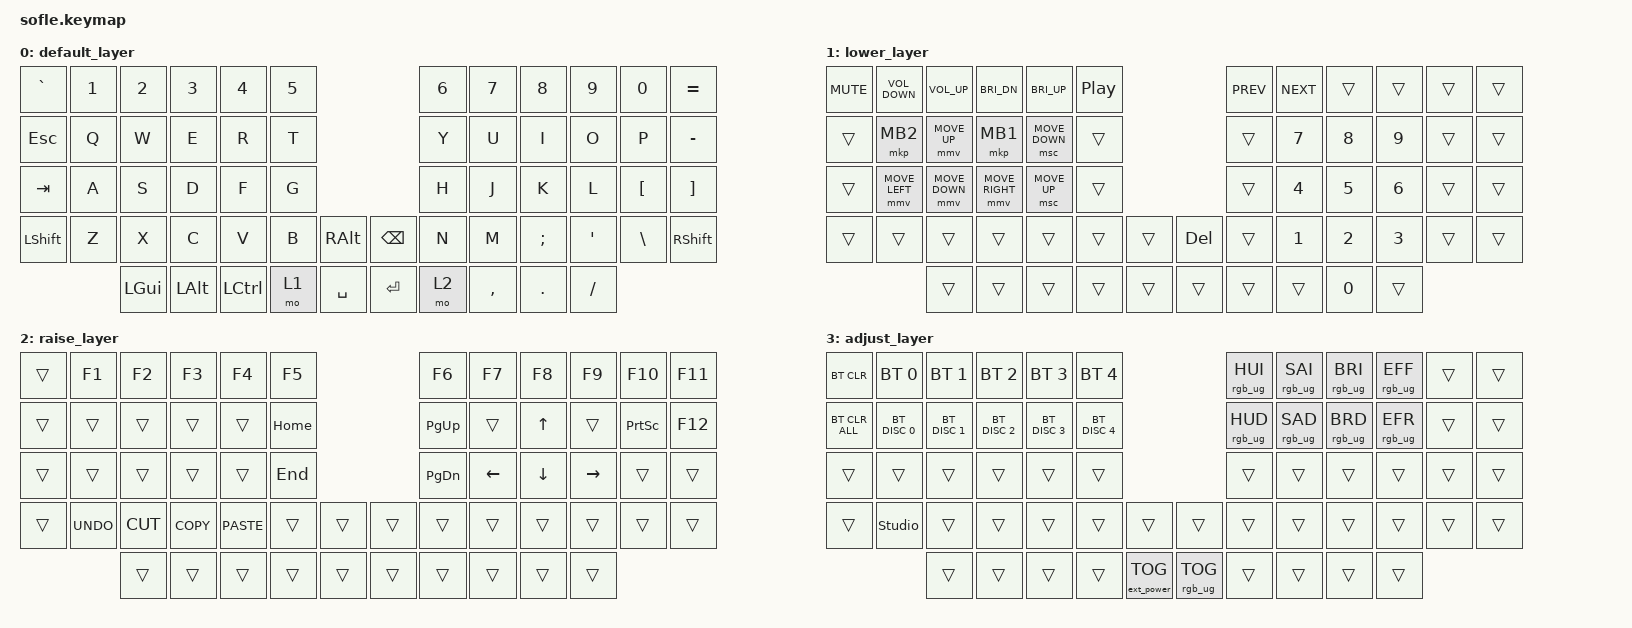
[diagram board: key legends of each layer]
/*
 * Copyright (c) 2020 The ZMK Contributors
 *
 * SPDX-License-Identifier: MIT
 */

#include <behaviors.dtsi>
#include <dt-bindings/zmk/keys.h>
#include <dt-bindings/zmk/bt.h>
#include <dt-bindings/zmk/ext_power.h>
#include <dt-bindings/zmk/rgb.h>
#define ZMK_POINTING_DEFAULT_MOVE_VAL 1500  // default: 600
#define ZMK_POINTING_DEFAULT_SCRL_VAL 20    // default: 10
#include <dt-bindings/zmk/pointing.h>

/*
 * Temporarily here because nice nano v2 spi is not defined on ZMK Yet
 * Source: https://github.com/zmkfirmware/zmk/blob/main/app/boards/shields/reviung41/boards/nice_nano.overlay
 * GitHub Issue: https://github.com/zmkfirmware/zmk/issues/885
 */

#include <dt-bindings/led/led.h>

&pinctrl {
    spi3_default: spi3_default {
        group1 {
            psels = <NRF_PSEL(SPIM_MOSI, 0, 8)>;
        };
    };

    spi3_sleep: spi3_sleep {
        group1 {
            psels = <NRF_PSEL(SPIM_MOSI, 0, 8)>;
            low-power-enable;
        };
    };
};

&spi3 {
    compatible = "nordic,nrf-spim";
    status = "okay";

    pinctrl-0 = <&spi3_default>;
    pinctrl-1 = <&spi3_sleep>;
    pinctrl-names = "default", "sleep";

    led_strip: ws2812@0 {
        compatible = "worldsemi,ws2812-spi";
        label = "WS2812";

        /* SPI */
        reg = <0>; /* ignored, but necessary for SPI bindings */
        spi-max-frequency = <4000000>;

        /* WS2812 */
        chain-length = <30>;
        spi-one-frame = <0x70>;
        spi-zero-frame = <0x40>;

        color-mapping = <LED_COLOR_ID_GREEN LED_COLOR_ID_RED LED_COLOR_ID_BLUE>;
    };
};

/ {
    chosen {
        zmk,underglow = &led_strip;
    };
};

/* END temporary RGB support section */


/ {
    combos {
        compatible = "zmk,combos";
        combo_esc {
            timeout-ms = <50>;
            key-positions = <0 1>;
            bindings = <&kp ESC>;
        };
        combo_del {
            timeout-ms = <50>;
            key-positions = <10 11>;
            bindings = <&kp DEL>;
        };
        combo_bspc {
            timeout-ms = <50>;
            key-positions = <22 23>;
            bindings = <&kp BSPC>;
        };
        combo_mb3 {
            timeout-ms = <50>;
            key-positions = <14 26>;
            bindings = <&mkp MB3>;
            layers = <1>;
        };
        combo_mb4 {
            timeout-ms = <50>;
            key-positions = <13 25>;
            bindings = <&mkp MB4>;
            layers = <1>;
        };
        combo_mb5 {
            timeout-ms = <50>;
            key-positions = <15 27>;
            bindings = <&mkp MB5>;
            layers = <1>;
        };
        combo_bootloader_left {
            // Pressing the 3 first keys on the keyboard will trigger &bootloader
            timeout-ms = <50>;
            key-positions = <0 1 2>;
            bindings = <&bootloader>;
        };
    };

    conditional_layers {
        compatible = "zmk,conditional-layers";
        tri_layer {
            if-layers = <1 2>;
            then-layer = <3>;
        };
    };

    keymap {
        compatible = "zmk,keymap";

        default_layer {
            bindings = <
//╭─────────────┬─────────────┬─────────────┬─────────────┬─────────────┬─────────────╮                             ╭─────────────┬─────────────┬─────────────┬─────────────┬─────────────┬─────────────╮
    &kp GRAVE     &kp N1        &kp N2        &kp N3        &kp N4        &kp N5                                      &kp N6        &kp N7        &kp N8        &kp N9        &kp N0        &kp EQUAL
//├─────────────┼─────────────┼─────────────┼─────────────┼─────────────┼─────────────┤                             ├─────────────┼─────────────┼─────────────┼─────────────┼─────────────┼─────────────┤
    &kp ESC       &kp Q         &kp W         &kp E         &kp R         &kp T                                       &kp Y         &kp U         &kp I         &kp O         &kp P         &kp MINUS
//├─────────────┼─────────────┼─────────────┼─────────────┼─────────────┼─────────────┤                             ├─────────────┼─────────────┼─────────────┼─────────────┼─────────────┼─────────────┤
    &kp TAB       &kp A         &kp S         &kp D         &kp F         &kp G                                       &kp H         &kp J         &kp K         &kp L         &kp LBKT      &kp RBKT
//├─────────────┼─────────────┼─────────────┼─────────────┼─────────────┼─────────────┼─────────────╮ ╭─────────────├─────────────┼─────────────┼─────────────┼─────────────┼─────────────┼─────────────┤
    &kp LSHFT     &kp Z         &kp X         &kp C         &kp V         &kp B         &kp RALT        &kp BSPC      &kp N         &kp M         &kp SEMI      &kp SQT       &kp BSLH      &kp RSHFT
//╰─────────────┴─────────────┼─────────────┼─────────────┼─────────────┼─────────────┤─────────────┤ ├─────────────┼─────────────┼─────────────┼─────────────┼─────────────┼─────────────┴─────────────╯
                                &kp LGUI      &kp LALT      &kp LCTRL     &mo 1         &kp SPACE       &kp RET       &mo 2         &kp COMMA     &kp DOT       &kp FSLH
//                            ╰─────────────┴─────────────┴─────────────┴─────────────┴─────────────╯ ╰─────────────┴─────────────┴─────────────┴─────────────┴─────────────╯
            >;

            sensor-bindings = <&inc_dec_kp PG_DN PG_UP &inc_dec_kp C_VOL_UP C_VOL_DN>;
        };

        lower_layer {
            bindings = <
//╭─────────────┬─────────────┬─────────────┬─────────────┬─────────────┬─────────────╮                             ╭─────────────┬─────────────┬─────────────┬─────────────┬─────────────┬─────────────╮
  &kp C_MUTE &kp C_VOLUME_DOWN&kp C_VOLUME_UP &kp C_BRI_DN  &kp C_BRI_UP  &kp C_PP                                    &kp C_PREV    &kp C_NEXT    &trans        &trans        &trans        &trans
//├─────────────┼─────────────┼─────────────┼─────────────┼─────────────┼─────────────┤                             ├─────────────┼─────────────┼─────────────┼─────────────┼─────────────┼─────────────┤
    &trans        &mkp MB2      &mmv MOVE_UP   &mkp MB1    &msc MOVE_DOWN &trans                                      &trans        &kp N7        &kp N8        &kp N9        &trans        &trans
//├─────────────┼─────────────┼─────────────┼─────────────┼─────────────┼─────────────┤                             ├─────────────┼─────────────┼─────────────┼─────────────┼─────────────┼─────────────┤
    &trans     &mmv MOVE_LEFT &mmv MOVE_DOWN &mmv MOVE_RIGHT &msc MOVE_UP &trans                                      &trans        &kp N4        &kp N5        &kp N6        &trans        &trans
//├─────────────┼─────────────┼─────────────┼─────────────┼─────────────┼─────────────┼─────────────╮ ╭─────────────├─────────────┼─────────────┼─────────────┼─────────────┼─────────────┼─────────────┤
    &trans        &trans        &trans        &trans        &trans        &trans        &trans          &kp DEL       &trans        &kp N1        &kp N2        &kp N3        &trans        &trans
//╰─────────────┴─────────────┼─────────────┼─────────────┼─────────────┼─────────────┤─────────────┤ ├─────────────┼─────────────┼─────────────┼─────────────┼─────────────┼─────────────┴─────────────╯
                                &trans        &trans        &trans        &trans        &trans          &trans        &trans        &trans        &kp N0        &trans
//                            ╰─────────────┴─────────────┴─────────────┴─────────────┴─────────────╯ ╰─────────────┴─────────────┴─────────────┴─────────────┴─────────────╯
            >;

            sensor-bindings = <&inc_dec_kp PG_DN PG_UP &inc_dec_kp C_VOL_UP C_VOL_DN>;
        };

        raise_layer {
            bindings = <
//╭─────────────┬─────────────┬─────────────┬─────────────┬─────────────┬─────────────╮                             ╭─────────────┬─────────────┬─────────────┬─────────────┬─────────────┬─────────────╮
    &trans        &kp F1        &kp F2        &kp F3        &kp F4        &kp F5                                      &kp F6        &kp F7        &kp F8        &kp F9        &kp F10       &kp F11
//├─────────────┼─────────────┼─────────────┼─────────────┼─────────────┼─────────────┤                             ├─────────────┼─────────────┼─────────────┼─────────────┼─────────────┼─────────────┤
    &trans        &trans        &trans        &trans        &trans        &kp HOME                                    &kp PG_UP     &trans        &kp UP        &trans        &kp PSCRN     &kp F12
//├─────────────┼─────────────┼─────────────┼─────────────┼─────────────┼─────────────┤                             ├─────────────┼─────────────┼─────────────┼─────────────┼─────────────┼─────────────┤
    &trans        &trans        &trans        &trans        &trans        &kp END                                     &kp PG_DN     &kp LEFT      &kp DOWN      &kp RIGHT     &trans        &trans
//├─────────────┼─────────────┼─────────────┼─────────────┼─────────────┼─────────────┼─────────────╮ ╭─────────────├─────────────┼─────────────┼─────────────┼─────────────┼─────────────┼─────────────┤
    &trans        &kp K_UNDO    &kp K_CUT     &kp K_COPY    &kp K_PASTE   &trans        &trans          &trans        &trans        &trans        &trans        &trans        &trans        &trans
//╰─────────────┴─────────────┼─────────────┼─────────────┼─────────────┼─────────────┤─────────────┤ ├─────────────┼─────────────┼─────────────┼─────────────┼─────────────┼─────────────┴─────────────╯
                                &trans        &trans        &trans        &trans        &trans          &trans        &trans        &trans        &trans        &trans
//                            ╰─────────────┴─────────────┴─────────────┴─────────────┴─────────────╯ ╰─────────────┴─────────────┴─────────────┴─────────────┴─────────────╯
            >;

            sensor-bindings = <&inc_dec_kp PG_DN PG_UP &inc_dec_kp C_VOL_UP C_VOL_DN>;
        };

        adjust_layer {
            bindings = <
//╭─────────────┬─────────────┬─────────────┬─────────────┬─────────────┬─────────────╮                             ╭─────────────┬─────────────┬─────────────┬─────────────┬─────────────┬─────────────╮
    &bt BT_CLR    &bt BT_SEL 0  &bt BT_SEL 1  &bt BT_SEL 2  &bt BT_SEL 3  &bt BT_SEL 4                             &rgb_ug RGB_HUI&rgb_ug RGB_SAI&rgb_ug RGB_BRI&rgb_ug RGB_EFF&trans        &trans
//├─────────────┼─────────────┼─────────────┼─────────────┼─────────────┼─────────────┤                             ├─────────────┼─────────────┼─────────────┼─────────────┼─────────────┼─────────────┤
  &bt BT_CLR_ALL &bt BT_DISC 0 &bt BT_DISC 1 &bt BT_DISC 2 &bt BT_DISC 3 &bt BT_DISC 4                             &rgb_ug RGB_HUD&rgb_ug RGB_SAD&rgb_ug RGB_BRD&rgb_ug RGB_EFR&trans        &trans
//├─────────────┼─────────────┼─────────────┼─────────────┼─────────────┼─────────────┤                             ├─────────────┼─────────────┼─────────────┼─────────────┼─────────────┼─────────────┤
    &trans        &trans        &trans        &trans        &trans        &trans                                      &trans        &trans        &trans        &trans        &trans        &trans
//├─────────────┼─────────────┼─────────────┼─────────────┼─────────────┼─────────────┼─────────────╮ ╭─────────────├─────────────┼─────────────┼─────────────┼─────────────┼─────────────┼─────────────┤
    &trans      &studio_unlock  &trans        &trans        &trans        &trans        &trans          &trans        &trans        &trans        &trans        &trans        &trans        &trans
//╰─────────────┴─────────────┼─────────────┼─────────────┼─────────────┼─────────────┤─────────────┤ ├─────────────┼─────────────┼─────────────┼─────────────┼─────────────┼─────────────┴─────────────╯
                                &trans        &trans        &trans        &trans    &ext_power EP_TOG &rgb_ug RGB_TOG &trans        &trans        &trans        &trans
//                            ╰─────────────┴─────────────┴─────────────┴─────────────┴─────────────╯ ╰─────────────┴─────────────┴─────────────┴─────────────┴─────────────╯
            >;

            sensor-bindings = <&inc_dec_kp PG_DN PG_UP &inc_dec_kp C_VOL_UP C_VOL_DN>;
        };

        extra1 {
            status = "reserved";
        };

        extra2 {
            status = "reserved";
        };
    };
};
